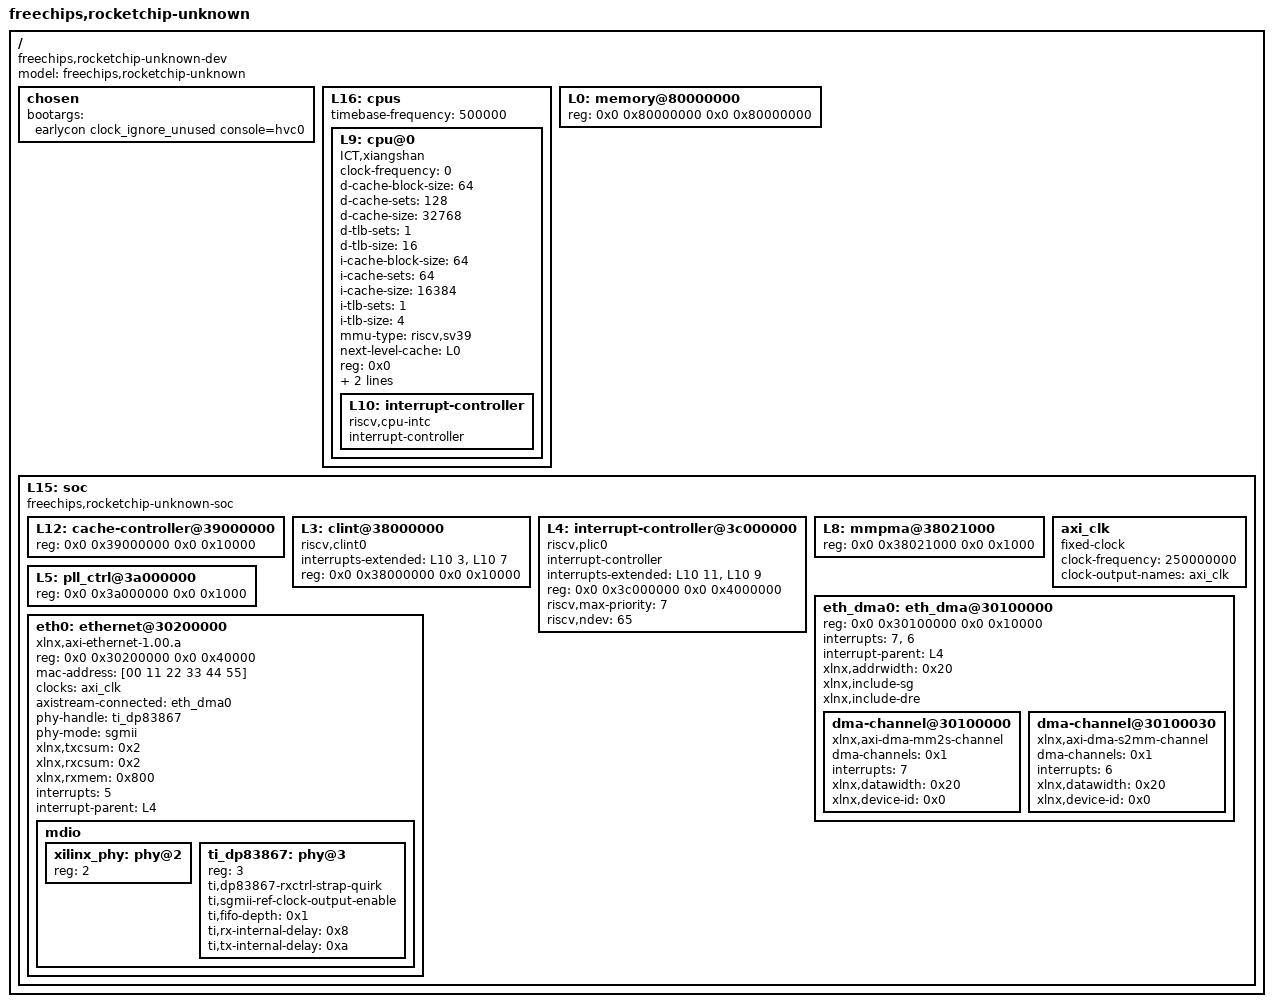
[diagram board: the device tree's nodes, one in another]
/dts-v1/;

/ {
	#address-cells = <2>;
	#size-cells = <2>;
	compatible = "freechips,rocketchip-unknown-dev";
	model = "freechips,rocketchip-unknown";

	// aliases {
	// 	serial0 = &uart0;
	// };

	chosen {
		bootargs = "earlycon clock_ignore_unused console=hvc0";
		//stdout-path = "serial0:115200n8";
	};
	
	L16: cpus {
		#address-cells = <1>;
		#size-cells = <0>;
		timebase-frequency = <500000>; // clk freq / 100
		L9: cpu@0 {
			clock-frequency = <0>;
			compatible = "ICT,xiangshan", "riscv";
			d-cache-block-size = <64>;
			d-cache-sets = <128>;
			d-cache-size = <32768>;
			d-tlb-sets = <1>;
			d-tlb-size = <16>;
			device_type = "cpu";
			i-cache-block-size = <64>;
			i-cache-sets = <64>;
			i-cache-size = <16384>;
			i-tlb-sets = <1>;
			i-tlb-size = <4>;
			mmu-type = "riscv,sv39";
			next-level-cache = <&L0>;
			reg = <0x0>;
			riscv,isa = "rv64imafdc";
			status = "okay";
			tlb-split;
			L10: interrupt-controller {
				#interrupt-cells = <1>;
				compatible = "riscv,cpu-intc";
				interrupt-controller;
			};
		};
	};
	L0: memory@80000000 {
		device_type = "memory";
		reg = <0x0 0x80000000 0x0 0x80000000>;
	};
	L15: soc {
		#address-cells = <2>;
		#size-cells = <2>;
		compatible = "freechips,rocketchip-unknown-soc", "simple-bus";
		ranges;
//		L11: bus-error-unit {
//			compatible = "sifive,buserror0";
//			interrupt-parent = <&L4>;
//			interrupts = <65>;
//		};
		L12: cache-controller@39000000 {
			reg = <0x0 0x39000000 0x0 0x10000>;
			reg-names = "control";
		};
		L3: clint@38000000 {
			compatible = "riscv,clint0";
			interrupts-extended = <&L10 3 &L10 7>;
			reg = <0x0 0x38000000 0x0 0x10000>;
			reg-names = "control";
		};
//		L6: debug-controller@38020000 {
//			compatible = "sifive,debug-013", "riscv,debug-013";
//			debug-attach = "jtag";
//			interrupts-extended = <&L10 65535>;
//			reg = <0x0 0x38020000 0x0 0x1000>;
//			reg-names = "control";
//		};
//		L2: error-device@0 {
//			compatible = "sifive,error0";
//			reg = <0x0 0x0 0x0 0x80000000>;
//		};
		L4: interrupt-controller@3c000000 {
			#interrupt-cells = <1>;
			compatible = "riscv,plic0";
			interrupt-controller;
			interrupts-extended = <&L10 11 &L10 9>;
			reg = <0x0 0x3c000000 0x0 0x4000000>;
			reg-names = "control";
			riscv,max-priority = <7>;
			riscv,ndev = <65>;
		};
		L8: mmpma@38021000 {
			reg = <0x0 0x38021000 0x0 0x1000>;
			reg-names = "control";
		};
		L5: pll_ctrl@3a000000 {
			reg = <0x0 0x3a000000 0x0 0x1000>;
			reg-names = "control";
		};
		// uart0: serial@40600000 {
		// 	compatible = "xlnx,opb-uartlite-1.00.b";
		// 	reg = <0x0 0x30000000 0x0 0x10000>;
		// 	port-number = <0>;
		// 	current-speed = <115200>;
		// 	interrupt-parent = <&L4>;
		// 	interrupts = <1>;
		// };
		axi_clk: axi_clk {
			#clock-cells = <0>;
			clock-frequency = <250000000>;
			clock-output-names = "axi_clk";
			compatible = "fixed-clock";
		};
		eth_dma0: eth_dma@30100000 {
			reg = <0x0 0x30100000 0x0 0x10000>;
			interrupts = <7>, <6>;  /*axi_ethernet_dma mm2s/s2mm INT*/
			interrupt-parent = <&L4>;
			xlnx,addrwidth = /bits/ 8 <0x20>;
			xlnx,include-sg;
			xlnx,include-dre;
			dma-channel@30100000 {
				compatible = "xlnx,axi-dma-mm2s-channel";
				dma-channels = <0x1>;
				interrupts = <7>;
				xlnx,datawidth = <0x20>;
				xlnx,device-id = <0x0>;
			};
			dma-channel@30100030 {
				compatible = "xlnx,axi-dma-s2mm-channel";
				dma-channels = <0x1>;
				interrupts = <6>;
				xlnx,datawidth = <0x20>;
				xlnx,device-id = <0x0>;
			};
		};
		eth0: ethernet@30200000 {
			compatible = "xlnx,axi-ethernet-1.00.a";
			reg = <0x0 0x30200000 0x0 0x40000>;
			reg-names = "control";
			status = "okay";
			mac-address = [00 11 22 33 44 55];
			clocks = <&axi_clk>;
			device_type = "network";
			axistream-connected = <&eth_dma0>;
			phy-handle = <&ti_dp83867>;
			phy-mode = "sgmii";
			xlnx,txcsum = <0x2>;
			xlnx,rxcsum = <0x2>;
        	xlnx,rxmem = <0x800>;
			interrupts = <5>;  /*axi_ethernet INT*/
			interrupt-parent = <&L4>;
			mdio: mdio {
				#address-cells = <1>;
				#size-cells = <0>;
				xilinx_phy: phy@2 {
					#phy-cells = <1>;
					device_type = "ethernet-phy";
					reg = <2>;
				};
				ti_dp83867: phy@3 {
					#phy-cells = <1>;
					device_type = "ethernet-phy";
					reg = <3>;
					ti,dp83867-rxctrl-strap-quirk;
					ti,sgmii-ref-clock-output-enable;
					ti,fifo-depth = <0x1>;
					ti,rx-internal-delay = <0x8>;
					ti,tx-internal-delay = <0xa>;
				};
			};
		};
	};
};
